# SF32LB52x register map
File version: 1.0
CPU: CM33 r0p1, little endian, MPU, FPU, 3 interrupt priority bits
Registers are 32-bit, read-write, reset 0x0 unless marked. A register's access mark holds for its fields unless they carry their own. Offsets are from the block's base; [hi:lo] are bit positions; {n}, {i} and the like mark numbered series; 'fields as' and 'values as' point back to an identical list.

## AUDCODEC
Base 0x50088000
0x00 ID reset 0xC0DEC000
  [31:0] FUNC — function id
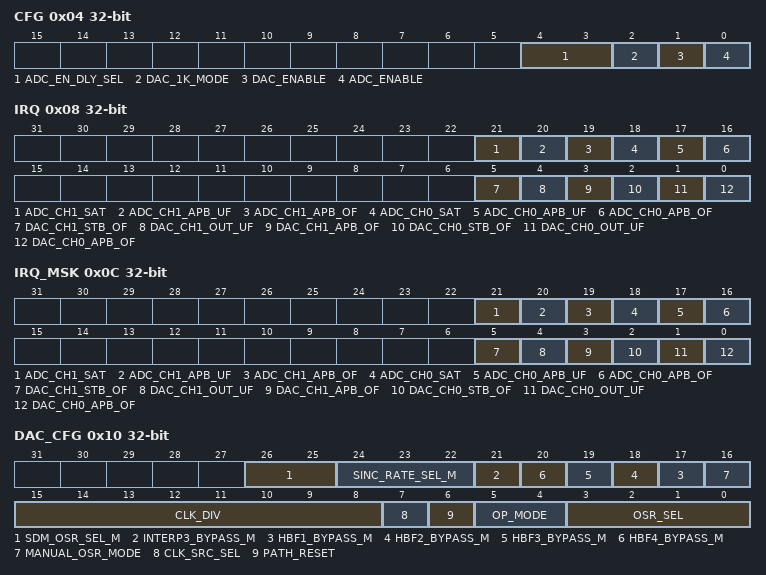
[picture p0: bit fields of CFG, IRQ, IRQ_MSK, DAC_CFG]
0x04 CFG
  [4:3] ADC_EN_DLY_SEL — codec adc enable delay count 0: no delay 1: 32 pclk 2: 64 pclk 3: 128 pclk
  [2] DAC_1K_MODE — codec dac sine 1k mode
  [1] DAC_ENABLE — dac codec enable
  [0] ADC_ENABLE — adc codec enable
0x08 IRQ
  [21] ADC_CH1_SAT — adc ch1 saturation interrupt
  [20] ADC_CH1_APB_UF — adc ch1 apb fifo underflow interrupt status. Write 1 to clear.
  [19] ADC_CH1_APB_OF — adc ch1 apb fifo overflow interrupt status. Write 1 to clear.
  [18] ADC_CH0_SAT — adc ch0 saturation interrupt
  [17] ADC_CH0_APB_UF — adc ch0 apb fifo underflow interrupt status. Write 1 to clear.
  [16] ADC_CH0_APB_OF — adc ch0 apb fifo overflow interrupt status. Write 1 to clear.
  [5] DAC_CH1_STB_OF — dac ch1 input stb fifo overflow interrupt status. Write 1 to clear.
  [4] DAC_CH1_OUT_UF — dac ch1 output fifo underflow interrupt status. Write 1 to clear.
  [3] DAC_CH1_APB_OF — dac ch1 apb fifo overflow interrupt status. Write 1 to clear.
  [2] DAC_CH0_STB_OF — dac ch0 input stb fifo overflow interrupt status. Write 1 to clear.
  [1] DAC_CH0_OUT_UF — dac ch0 output fifo underflow interrupt status. Write 1 to clear.
  [0] DAC_CH0_APB_OF — dac ch0 apb fifo overflow interrupt status. Write 1 to clear.
0x0C IRQ_MSK
  [21] ADC_CH1_SAT — interrupt mask. 0: mask the interrupt.
  [20] ADC_CH1_APB_UF — interrupt mask. 0: mask the interrupt.
  [19] ADC_CH1_APB_OF — interrupt mask. 0: mask the interrupt.
  [18] ADC_CH0_SAT — interrupt mask. 0: mask the interrupt.
  [17] ADC_CH0_APB_UF — interrupt mask. 0: mask the interrupt.
  [16] ADC_CH0_APB_OF — interrupt mask. 0: mask the interrupt.
  [5] DAC_CH1_STB_OF — interrupt mask. 0: mask the interrupt.
  [4] DAC_CH1_OUT_UF — interrupt mask. 0: mask the interrupt.
  [3] DAC_CH1_APB_OF — interrupt mask. 0: mask the interrupt.
  [2] DAC_CH0_STB_OF — interrupt mask. 0: mask the interrupt.
  [1] DAC_CH0_OUT_UF — interrupt mask. 0: mask the interrupt.
  [0] DAC_CH0_APB_OF — interrupt mask. 0: mask the interrupt.
0x10 DAC_CFG
  [26:25] SDM_OSR_SEL_M — 0:100 1:150 2:300 3:256
  [24:22] SINC_RATE_SEL_M — 0:25 1:50 2:16 3:32 4:64
  [21] INTERP3_BYPASS_M
  [n+16] HBF{n}_BYPASS_M (n=1..4)
  [16] MANUAL_OSR_MODE — set 1 to manually set hbf, interp3, sinc and sdm module
  [15:8] CLK_DIV — dac clock divider
  [7] CLK_SRC_SEL — dac clock source select 1: pll 0: xtal
  [6] PATH_RESET — dac path reset, set 1 to reset dac path
  [5:4] OP_MODE — dac operation mode 2'h0: normal mode: send dac data through tx interface 2'h1: apb mode: send dac data out through apb interface 2'h2, 2'h3: reserved
  [3:0] OSR_SEL — DAC oversample rate 4'b0000: 100 4'b0001: 150 4'b0010: 200 4'b0011: 300(sdm osr = 150) 4'b0100: 300(sdm osr = 300) 4'b0101: 400 4'b0110: 600 4'b0111: 800 4'b1000: 1200 4'b1001: 256 4'b1010: 512 4'b1011: 1024 other: reserved
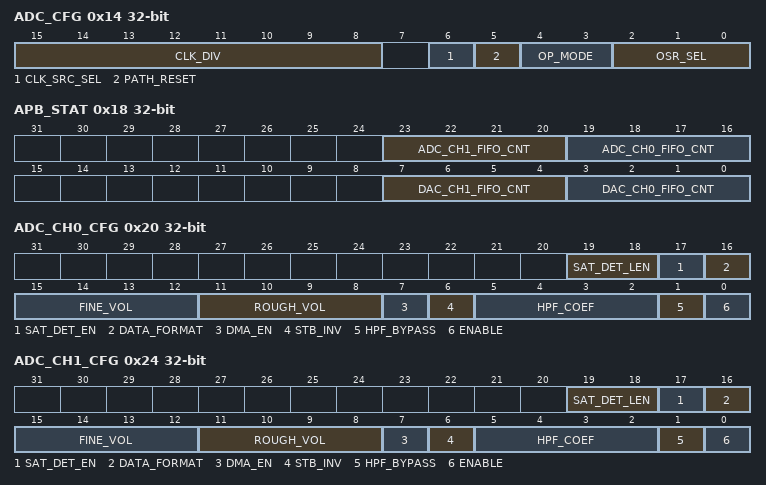
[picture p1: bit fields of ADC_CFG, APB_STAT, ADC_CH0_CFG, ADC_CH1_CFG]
0x14 ADC_CFG
  [15:8] CLK_DIV — adc clock divider
  [6] CLK_SRC_SEL — adc clock source select 1: pll 0: xtal
  [5] PATH_RESET — adc path reset, set 1 to reset adc path
  [4:3] OP_MODE — adc operation mode 2'h0: normal mode: send adc data out through rx interface 2'h1: apb mode: send adc data out through apb interface 2'h2: raw data apb mode: send adc raw data out through apb interface 2'h3: reserved
  [2:0] OSR_SEL — ADC oversample rate 3'b000: 200 3'b001: 300 3'b010: 400 3'b011: 600 other: reserved
0x18 APB_STAT
  [23:20] ADC_CH1_FIFO_CNT, [19:16] ADC_CH0_FIFO_CNT, [7:4] DAC_CH1_FIFO_CNT, [3:0] DAC_CH0_FIFO_CNT
0x20 ADC_CH0_CFG
  [19:18] SAT_DET_LEN — adc saturation detect pattern length 2'b00: 16 2'b01: 24 2'b10: 32 2'b11: 48
  [17] SAT_DET_EN — adc saturation detect
  [16] DATA_FORMAT — adc data format 1: 16-bit 0: 24-bit this bit only affect the data format accessed by apb interface. For 24-bit, every 24-bit data occupied 32-bit word. Bit[31:24] are zeros. For 16-bit mode, every 32-bit word contains two 16-bit audio data{D1, D0}
  [15:12] FINE_VOL — adc fine volume control range from 0dB to 6dB step is 0.5dB 4'h0: 0dB 4'h1: 0.5dB ...... 4'hb: 5.5dB 4'hc, 4'hd, 4'he, 4'hf: mute
  [11:8] ROUGH_VOL — adc rough volume control range from -60dB to 30dB step is 6dB 4'h0: -60dB 4'h1: -54dB ...... 4'ha: 0dB ...... 4'he: 24dB 4'hf: 30dB
  [7] DMA_EN — dma interface enable in apb mode and raw data apb mode 1: enable adc ch0 dma request interface 0: disable adc ch0 dma request interface
  [6] STB_INV — adc strobe inverter
  [5:2] HPF_COEF — high-pass filter coefficient
  [1] HPF_BYPASS — high-pass filter bypass
  [0] ENABLE — adc channel enable
0x24 ADC_CH1_CFG
  fields as ADC_CH0_CFG
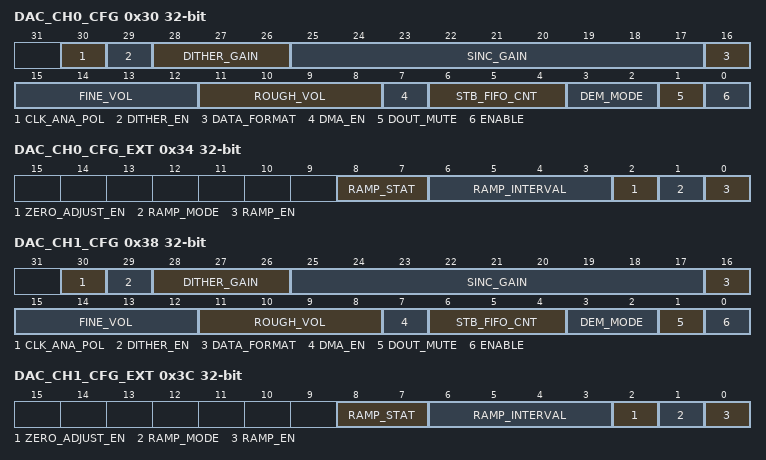
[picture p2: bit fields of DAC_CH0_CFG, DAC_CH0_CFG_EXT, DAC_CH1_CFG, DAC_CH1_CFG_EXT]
0x30 DAC_CH0_CFG
  [30] CLK_ANA_POL — analog dac clock polarity
  [29] DITHER_EN — sdm dither enable
  [28:26] DITHER_GAIN — sdm dither gain
  [25:17] SINC_GAIN — dac sinc filter gain
  [16] DATA_FORMAT — dac data format 1: 16-bit 0: 24-bit this bit only affect the data format accessed by apb interface. For 24-bit, every 24-bit data occupied 32-bit word. Bit[31:24] are zeros. For 16-bit mode, every 32-bit word contains two 16-bit audio data{D1, D0}
  [15:12] FINE_VOL — dac fine volume control range from 0dB to 6dB step is 0.5dB 4'h0: 0dB 4'h1: 0.5dB ...... 4'hb: 5.5dB 4'hc, 4'hd, 4'he, 4'hf: mute
  [11:8] ROUGH_VOL — dac rough volume control range from -36dB to 54dB step is 6dB 4'h0: -36dB 4'h1: -30dB ...... 4'h6: 0dB ...... 4'he: 48dB 4'hf: 54dB
  [7] DMA_EN — dma interface enable in apb mode 1: enable dac ch0 dma request interface 0: disable dac ch0 dma request interface
  [6:4] STB_FIFO_CNT — dac input stb fifo cnt
  [3:2] DEM_MODE — dem output mode 2'h0: no shift for dem output 2'h1: shift dem output incrementally 2'h2: shift dem output according to input 2'h3: reserved
  [1] DOUT_MUTE — dac output mute, set 1 to mute the output
  [0] ENABLE — dac channel enable
0x34 DAC_CH0_CFG_EXT
  [8:7] RAMP_STAT — ramp module status
  [6:3] RAMP_INTERVAL — volume ramp interval.
  [2] ZERO_ADJUST_EN — enable volume adjustment during 0 volume cross.
  [1] RAMP_MODE — volume ramp mode: 1: slowly ramp to target volume. Step is 0.5db 0: directly ramp to target volume.
  [0] RAMP_EN — volume ramp enable
0x38 DAC_CH1_CFG
  fields as DAC_CH0_CFG
0x3C DAC_CH1_CFG_EXT
  fields as DAC_CH0_CFG_EXT
0x40 ADC_CH0_ENTRY
  [31:0] DATA — adc channel0 data output
0x44 ADC_CH1_ENTRY
  [31:0] DATA — adc channel1 data output
0x50 DAC_CH0_ENTRY
  [31:0] DATA — dac channel0 data input
0x54 DAC_CH1_ENTRY
  [31:0] DATA — dac channel0 data input
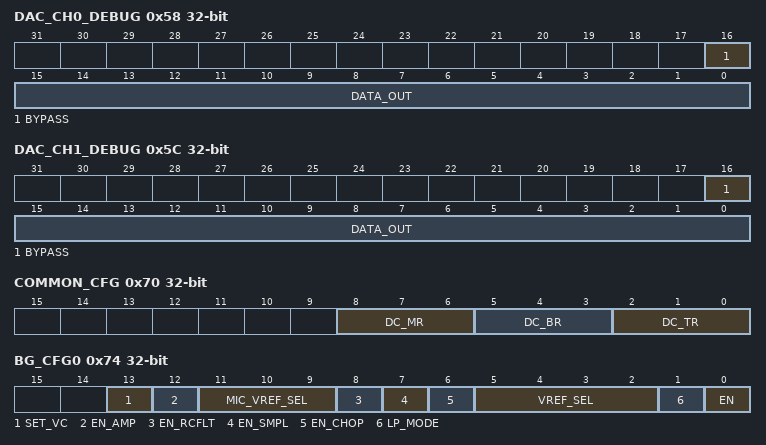
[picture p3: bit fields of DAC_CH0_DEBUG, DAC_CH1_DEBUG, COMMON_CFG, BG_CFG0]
0x58 DAC_CH0_DEBUG
  [16] BYPASS — debug bypass mode
  [15:0] DATA_OUT — debug dac output
0x5C DAC_CH1_DEBUG
  [16] BYPASS — debug bypass mode
  [15:0] DATA_OUT — debug dac output
0x60 DAC_CH0_DC
  [23:0] OFFSET — dac ch0 dc offset
0x64 DAC_CH1_DC
  [23:0] OFFSET — dac ch1 dc offset
0x70 COMMON_CFG
  [8:6] DC_MR — DC test Macro select
  [5:3] DC_BR — DC test Block select
  [2:0] DC_TR — DC test point select
0x74 BG_CFG0
  [13] SET_VC
  [12] EN_AMP — enable bg opamp
  [11:9] MIC_VREF_SEL — select mic vref
  [8] EN_RCFLT — enable bandgap rc filter
  [7] EN_SMPL — enable bandgap sample
  [6] EN_CHOP — enable bandgap chop
  [5:2] VREF_SEL — set vref, 12: 2.2V
  [1] LP_MODE — 1: bandgap lp mode
  [0] EN — enable bandgap
0x78 BG_CFG1
  [31:0] SAMPCLK_HI — bg sample clock high cycle width, based on 0: stop bg sample clock
0x7C BG_CFG2
  [31:0] SAMPCLK_LO — bg sample clock low cycle width. 0: stop bg sample clock
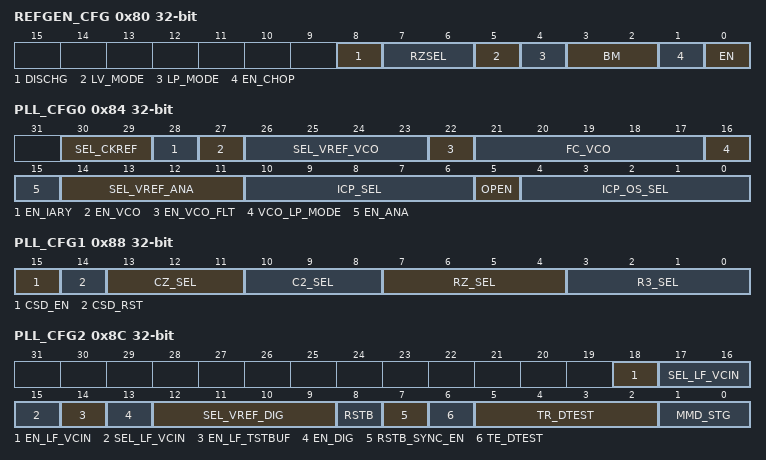
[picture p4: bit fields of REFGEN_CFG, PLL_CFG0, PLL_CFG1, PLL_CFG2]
0x80 REFGEN_CFG
  [8] DISCHG — discharge vref
  [7:6] RZSEL — sel Rz, 0: 1uF cap
  [5] LV_MODE — low vol mode
  [4] LP_MODE — 1: lpmode(adc), 0:dac
  [3:2] BM — bias mode
  [1] EN_CHOP — enable ref gen chop
  [0] EN — enable ref gen
0x84 PLL_CFG0
  [30:29] SEL_CKREF — select ref clock, 2: 24MHz
  [28] EN_IARY — enable I array
  [27] EN_VCO — enable vco
  [26:23] SEL_VREF_VCO — ldo vref, 7:1.1V
  [22] EN_VCO_FLT — vco bais filter
  [21:17] FC_VCO — VCO Fcode
  [16] VCO_LP_MODE — 1: lp mode
  [15] EN_ANA — enable ana block
  [14:11] SEL_VREF_ANA — ldo vref, 7:1.1V
  [10:6] ICP_SEL — select Icp, 1:1.25u
  [5] OPEN — 1: pll open
  [4:0] ICP_OS_SEL — Icp os
0x88 PLL_CFG1
  [15] CSD_EN — enable CSD
  [14] CSD_RST — reset CSD, high active
  [13:11] CZ_SEL — select Cz
  [10:8] C2_SEL — select C2
  [7:4] RZ_SEL — select Rz
  [3:0] R3_SEL — select R3
0x8C PLL_CFG2
  [18] EN_LF_VCIN — enable vcin for vco
  [17:15] SEL_LF_VCIN — select vcin, 4: 550mV
  [14] EN_LF_TSTBUF — enable vctrl buf
  [13] EN_DIG — enable dig block
  [12:9] SEL_VREF_DIG — ldo vref, 7:1.1V
  [8] RSTB — resetb
  [7] RSTB_SYNC_EN — resetb sync
  [6] TE_DTEST — enable dtest
  [5:2] TR_DTEST — select dtest
  [1:0] MMD_STG
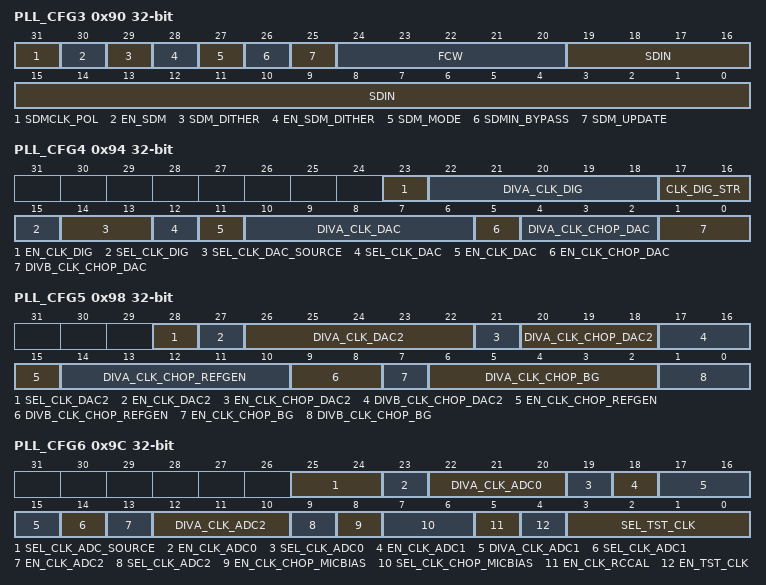
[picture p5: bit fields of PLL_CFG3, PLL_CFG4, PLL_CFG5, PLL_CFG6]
0x90 PLL_CFG3
  [31] SDMCLK_POL — sdm dig clk polarity
  [30] EN_SDM — enable sdm
  [29] SDM_DITHER
  [28] EN_SDM_DITHER — enable sdm dither
  [27] SDM_MODE
  [26] SDMIN_BYPASS — 1: bypass FCW and SDIN sdm control signal
  [25] SDM_UPDATE — write 1 to update FCW and SDIN value
  [24:20] FCW
  [19:0] SDIN — sdm input
0x94 PLL_CFG4
  [23] EN_CLK_DIG — enable dig clk
  [22:18] DIVA_CLK_DIG — DIVA dig clk
  [17:16] CLK_DIG_STR — strength
  [15] SEL_CLK_DIG — select dig clk 0: pll 1: 24MHz from xtal
  [14:13] SEL_CLK_DAC_SOURCE — 0: xtal 1: pll
  [12] SEL_CLK_DAC — 1: select 9.6MHz as DAC clock
  [11] EN_CLK_DAC — enable dac clk
  [10:6] DIVA_CLK_DAC — DIVA dac clk
  [5] EN_CLK_CHOP_DAC — enable dac chop clk
  [4:2] DIVA_CLK_CHOP_DAC — DIVA dac chop clk
  [1:0] DIVB_CLK_CHOP_DAC — DIVB dac chop clk
0x98 PLL_CFG5
  [28] SEL_CLK_DAC2 — 1: select 9.6MHz as DAC clock
  [27] EN_CLK_DAC2 — enable dac2 clk
  [26:22] DIVA_CLK_DAC2 — DIVA dac2 clk
  [21] EN_CLK_CHOP_DAC2 — enable dac2 chop clk
  [20:18] DIVA_CLK_CHOP_DAC2 — DIVA dac2 chop clk
  [17:16] DIVB_CLK_CHOP_DAC2 — DIVB dac2 chop clk
  [15] EN_CLK_CHOP_REFGEN — enable ref chop clk
  [14:10] DIVA_CLK_CHOP_REFGEN — DIVA ref chop clk
  [9:8] DIVB_CLK_CHOP_REFGEN — DIVB ref chop clk
  [7] EN_CLK_CHOP_BG — enable bg chop clk
  [6:2] DIVA_CLK_CHOP_BG — DIVA bg chop clk
  [1:0] DIVB_CLK_CHOP_BG — DIVB bg chop clk
0x9C PLL_CFG6
  [25:24] SEL_CLK_ADC_SOURCE — 0: xtal, 1: pll
  [23] EN_CLK_ADC0 — enable adc0 clk
  [22:20] DIVA_CLK_ADC0 — DIVA adc0 clk
  [19] SEL_CLK_ADC0 — select adc0 clk
  [18] EN_CLK_ADC1 — enable adc1 clk
  [17:15] DIVA_CLK_ADC1 — DIVA adc1 clk
  [14] SEL_CLK_ADC1 — select adc1 clk
  [13] EN_CLK_ADC2 — enable adc2 clk
  [12:10] DIVA_CLK_ADC2 — DIVA adc2 clk
  [9] SEL_CLK_ADC2 — select adc2 clk
  [8] EN_CLK_CHOP_MICBIAS — enable micbias chop clk
  [7:6] SEL_CLK_CHOP_MICBIAS — select micbias chop clk
  [5] EN_CLK_RCCAL — enable RC CAL clk
  [4] EN_TST_CLK — enable test clk
  [3:0] SEL_TST_CLK — select clk to test
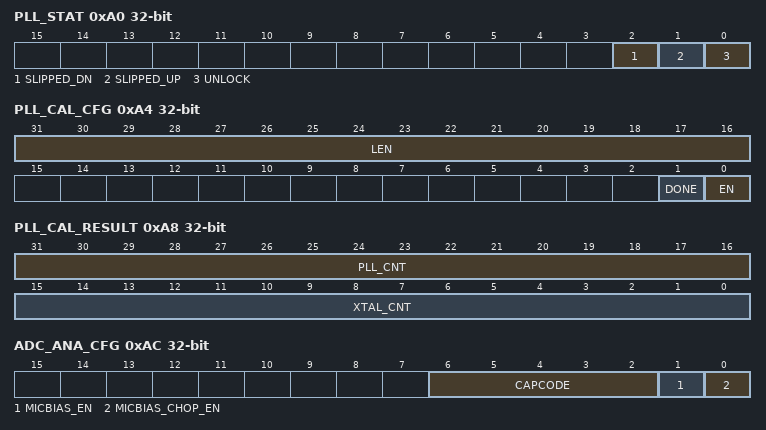
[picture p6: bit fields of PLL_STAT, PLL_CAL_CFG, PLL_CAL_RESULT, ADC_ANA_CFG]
0xA0 PLL_STAT
  [2] SLIPPED_DN — slip dn
  [1] SLIPPED_UP — slip up
  [0] UNLOCK — 1:pll unlock
0xA4 PLL_CAL_CFG
  [31:16] LEN — calibration length
  [1] DONE — calibration done
  [0] EN — calibration enable
0xA8 PLL_CAL_RESULT
  [31:16] PLL_CNT — pll calibration counter result
  [15:0] XTAL_CNT — xtal calibration counter result
0xAC ADC_ANA_CFG
  [6:2] CAPCODE — ADC cap code
  [1] MICBIAS_EN — micbias enable
  [0] MICBIAS_CHOP_EN — micbias chopping enable
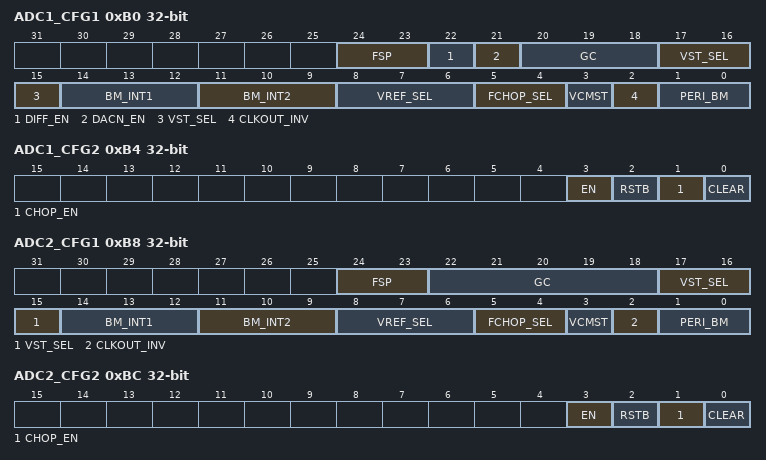
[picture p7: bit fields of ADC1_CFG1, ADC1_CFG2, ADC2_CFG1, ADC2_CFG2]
0xB0 ADC1_CFG1
  [24:23] FSP — sampling frequency: 0x0:9.6M 0x1:8.82M 0x2:4.8M 0x3:4.41M
  [22] DIFF_EN — enable differential input mode
  [21] DACN_EN — enable negative DAC1
  [20:18] GC — gaincode: 0x0:-6dB 0x1:0dB ... 0x4:18dB
  [17:15] VST_SEL — start voltage 0x0:VCM+200mV 0x7:VCM+550mV
  [14:12] BM_INT1 — bias mode of first opamp
  [11:9] BM_INT2 — bias mode of 2nd and 3rd opamp
  [8:6] VREF_SEL — vref code from proper vcm in flash7 0x0:1.2V 0x1:1.4V 0x7:2.6V
  [5:4] FCHOP_SEL — chopping frequncy 0x0:÷8 0x1:÷16 0x2:÷32 0x3:÷64
  [3] VCMST — VCM quick settling
  [2] CLKOUT_INV — inverse output clock
  [1:0] PERI_BM — peripheral circuits biasmode
0xB4 ADC1_CFG2
  [3] EN — enable adc
  [2] RSTB — reset adc
  [1] CHOP_EN — chopping enable
  [0] CLEAR — clear adc
0xB8 ADC2_CFG1
  [24:23] FSP — sampling frequency: 0x0:9.6M 0x1:8.82M 0x2:4.8M 0x3:4.41M
  [22:18] GC — gaincode: 0x0:-10dB 0xa:0dB 0x1e:20dB
  [17:15] VST_SEL — start voltage 0x0:VCM+200mV 0x7:VCM+550mV
  [14:12] BM_INT1 — bias mode of first opamp
  [11:9] BM_INT2 — bias mode of 2nd and 3rd opamp
  [8:6] VREF_SEL — vref code from proper vcm in flash7 0x0:1.2V 0x1:1.4V 0x7:2.6V
  [5:4] FCHOP_SEL — chopping frequncy 0x0:÷8 0x1:÷16 0x2:÷32 0x3:÷64
  [3] VCMST — VCM quick settling
  [2] CLKOUT_INV — inverse output clock
  [1:0] PERI_BM — peripheral circuits biasmode
0xBC ADC2_CFG2
  fields as ADC1_CFG2
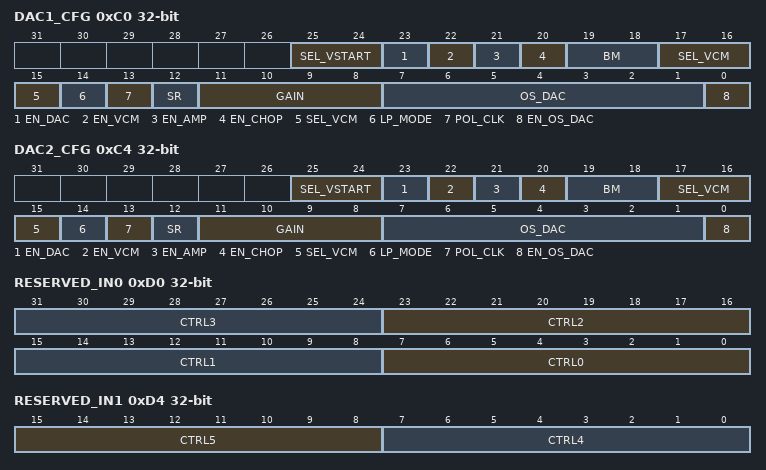
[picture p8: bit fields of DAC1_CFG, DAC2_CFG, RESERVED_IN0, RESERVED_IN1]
0xC0 DAC1_CFG
  [25:24] SEL_VSTART — select Vstart
  [23] EN_DAC — enable dac
  [22] EN_VCM — enable vcm
  [21] EN_AMP — enable amp
  [20] EN_CHOP — enable chop
  [19:18] BM — bias mode
  [17:15] SEL_VCM — select vcm
  [14] LP_MODE — 0: 3.3V sup, 1: 1.8V supply
  [13] POL_CLK — dac clk polarity
  [12] SR — dac short switch
  [11:8] GAIN — dac gain
  [7:1] OS_DAC
  [0] EN_OS_DAC — enable os dac
0xC4 DAC2_CFG
  fields as DAC1_CFG
0xD0 RESERVED_IN0
  [8n+7:8n] CTRL{n} (n=0..3) — reserved control {n}
0xD4 RESERVED_IN1
  [15:8] CTRL5 — reserved control 5
  [7:0] CTRL4 — reserved control 4
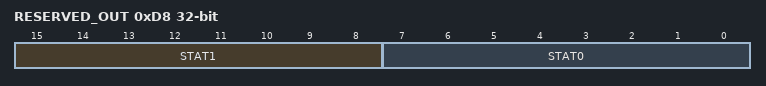
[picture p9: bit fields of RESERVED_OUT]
0xD8 RESERVED_OUT
  [15:8] STAT1 — reserved status1
  [7:0] STAT0 — reserved status0
